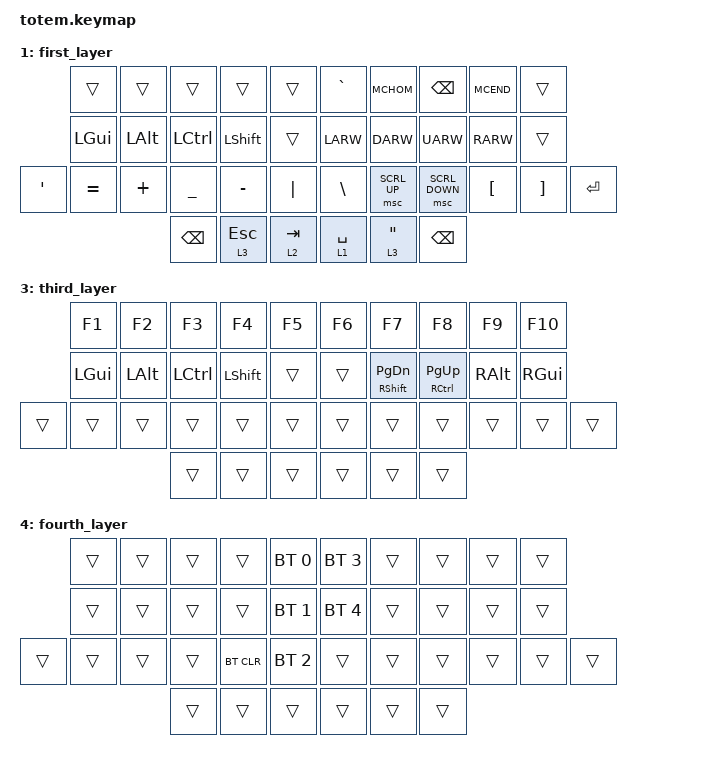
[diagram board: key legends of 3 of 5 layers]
//
//                                                        ▀▀▀▀▀     ▀▀▀▀▀          ▀▀█▀▀
//                                                        ▄▀▀▀▄  ▄  ▄▀▀▀▄  ▄  ▄▀▀▀▄  █  ▄▀▀▀▄
//                                                        █   █  █  █   █  █  █   █  █  █   █
//                                                         ▀▀▀   █   ▀▀▀   █   ▀▀▀   ▀   ▀▀▀
//                                                               █      ▄▄▄█▄▄▄    █   █  
//                                                               ▀      █  █  █     █▄█
//                                                             ▀▀▀▀▀    █  █  █      ▀
//                                                                      ▀  ▀  ▀
//
// ▄▄▄▄▄▄▄▄▄▄▄▄▄▄▄▄▄▄▄▄▄▄▄▄▄▄▄▄▄▄▄▄▄▄▄▄▄▄▄▄▄▄▄▄▄▄▄▄▄▄▄▄▄▄▄▄▄▄▄▄▄▄▄▄▄▄▄▄▄▄▄▄▄▄▄▄▄▄▄▄▄▄▄▄▄▄▄▄▄▄▄▄▄▄▄▄▄▄▄▄▄▄▄▄▄▄▄▄▄▄▄▄▄▄▄▄▄▄▄▄▄▄▄▄▄▄▄▄▄▄▄▄▄▄▄▄▄▄▄▄▄▄▄▄▄▄▄▄▄
       

#include <behaviors.dtsi>
#include <dt-bindings/zmk/keys.h>
#include <dt-bindings/zmk/bt.h>
#include <dt-bindings/zmk/pointing.h>

#define HRML(k1,k2,k3,k4) &ht LGUI k1  &ht LALT k2  &ht LCTRL k3  &ht LSHFT k4
#define HRMR(k1,k2,k3,k4) &ht RSHFT k1  &ht RCTRL k2  &ht RALT k3  &ht RGUI k4
#define MCHOM LG(LARW)
#define MCEND LG(RARW)

/ {
    behaviors {
        ht: hold_tap {
            compatible = "zmk,behavior-hold-tap";
            #binding-cells = <2>;
            flavor = "tap-preferred";
            tapping-term-ms = <220>;
            quick-tap-ms = <150>;
            require-prior-idle-ms = <100>;
            bindings = <&kp>, <&kp>;
        };
    };

    keymap {
        compatible = "zmk,keymap";

        default_layer {
            bindings = <
            &kp Q      &kp W      &kp E      &kp R      &kp T          &kp Y      &kp U      &kp I      &kp O      &kp P
            HRML(A,        S,         D,         F)     &kp G          &kp H      HRMR(J,        K,         L,       SEMI)
   &kp SQT  &lt 4 Z    &kp X      &kp C      &kp V      &kp B          &kp N      &kp M      &kp COMMA  &kp DOT    &kp FSLH   &kp RET
                               &kp BSPC  &lt 3 ESC  &lt 2 TAB          &lt 1 SPC  &lt 3 SQT &kp BSPC
            >;
        };

        first_layer {
            bindings = <
            &trans     &trans     &trans     &trans     &trans         &kp GRAVE  &kp MCHOM    &kp BSPC       &kp MCEND  &trans
            &kp LGUI   &kp LALT   &kp LCTRL  &kp LSHFT  &trans         &kp LARW   &kp DARW     &kp UARW       &kp RARW   &trans
   &kp SQT  &kp EQUAL  &kp PLUS   &kp UNDER  &kp MINUS  &kp PIPE       &kp BSLH   &msc SCRL_UP &msc SCRL_DOWN &kp LBKT   &kp RBKT   &kp RET
                                  &kp BSPC  &lt 3 ESC  &lt 2 TAB       &lt 1 SPC  &lt 3 DQT &kp BSPC
            >;
        };

        second_layer {
            bindings = <
            &kp N1     &kp N2     &kp N3     &kp N4     &kp N5         &kp N6     &kp N7     &kp N8     &kp N9     &kp N0
            HRML(EXCL, AT,        HASH,      DLLR)      &kp PRCNT      &kp CARET  HRMR(AMPS, STAR,      LPAR,      RPAR)
   &kp SQT  &kp EQUAL  &kp PLUS   &kp UNDER  &kp MINUS  &kp PIPE       &kp BSLH   &kp LBRC   &kp RBRC   &kp LBKT   &kp RBKT   &trans
                                  &kp BSPC  &lt 3 ESC  &lt 2 TAB       &lt 1 SPC  &lt 3 DQT &kp BSPC
            >;
        };

        third_layer {
            bindings = <
            &kp F1     &kp F2     &kp F3     &kp F4     &kp F5         &kp F6     &kp F7     &kp F8     &kp F9     &kp F10
            &kp LGUI   &kp LALT   &kp LCTRL  &kp LSHFT  &trans         &trans     &mt RSHFT PG_DN  &mt RCTRL PG_UP  &kp RALT  &kp RGUI
  &trans    &trans     &trans     &trans     &trans     &trans         &trans     &trans     &trans     &trans     &trans     &trans
                                  &trans     &trans     &trans         &trans     &trans     &trans
            >;
        };

        fourth_layer {
            bindings = <
            &trans     &trans     &trans     &trans     &bt BT_SEL 0   &bt BT_SEL 3  &trans   &trans     &trans     &trans
            &trans     &trans     &trans     &trans     &bt BT_SEL 1   &bt BT_SEL 4  &trans   &trans     &trans     &trans
  &trans    &trans     &trans     &trans     &bt BT_CLR &bt BT_SEL 2   &trans     &trans      &trans     &trans     &trans     &trans
                                  &trans     &trans     &trans         &trans     &trans     &trans
            >;
        };
    };
};
